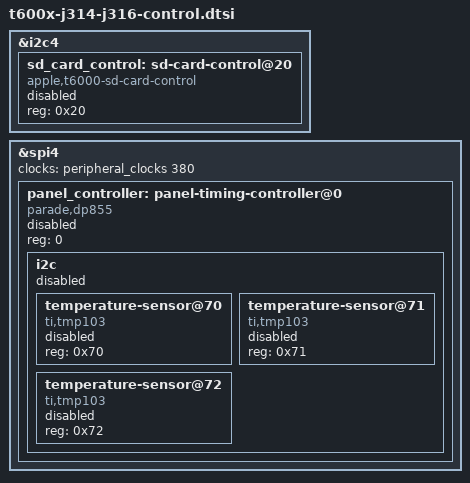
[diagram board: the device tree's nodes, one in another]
// SPDX-License-Identifier: GPL-2.0+ OR MIT
/* Populated board control clients. Transport ownership is not transferred. */

&i2c4 {
	/*
	 * Unidentified client: a bare read may change its state. Keep it
	 * disabled, and never probe, scan or read address 0x20. SD card
	 * detection does not use it.
	 */
	sd_card_control: sd-card-control@20 {
		compatible = "apple,t6000-sd-card-control", "apple,sd-card-control";
		reg = <0x20>;
		status = "disabled";
	};
};

&spi4 {
	clocks = <&peripheral_clocks 380>;

	panel_controller: panel-timing-controller@0 {
		compatible = "parade,dp855";
		reg = <0>;
		status = "disabled";

		i2c {
			#address-cells = <1>;
			#size-cells = <0>;
			status = "disabled";
			temperature-sensor@70 {
				compatible = "ti,tmp103";
				reg = <0x70>;
				status = "disabled";
			};
			temperature-sensor@71 {
				compatible = "ti,tmp103";
				reg = <0x71>;
				status = "disabled";
			};
			temperature-sensor@72 {
				compatible = "ti,tmp103";
				reg = <0x72>;
				status = "disabled";
			};
		};
	};
};
